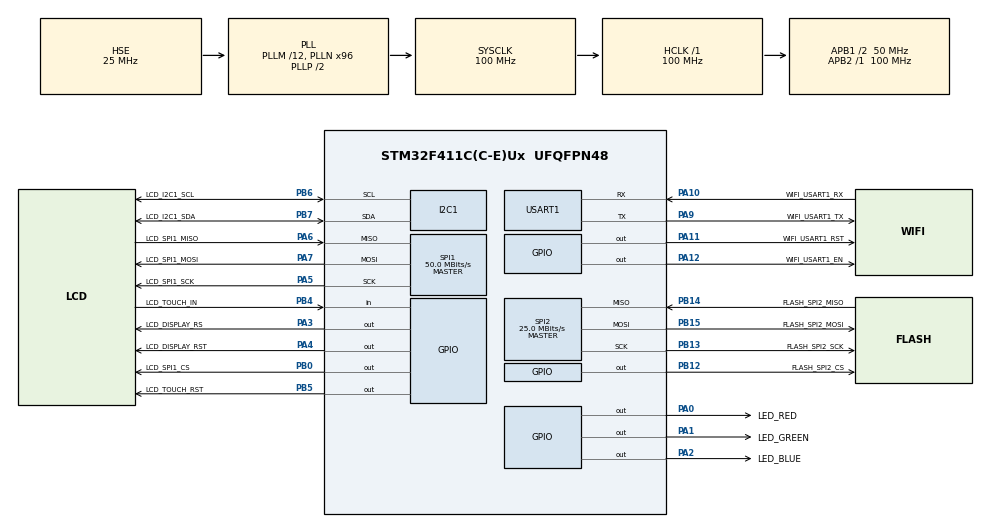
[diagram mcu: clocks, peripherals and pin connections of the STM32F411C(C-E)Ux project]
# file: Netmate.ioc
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FREERTOS.Tasks01=defaultTask,24,128,StartDefaultTask,Default,NULL,Dynamic,NULL,NULL
IWDG.Prescaler=IWDG_PRESCALER_64
Mcu.Family=STM32F4
Mcu.Name=STM32F411C(C-E)Ux
Mcu.Package=UFQFPN48
NVIC.PriorityGroup=NVIC_PRIORITYGROUP_4
NVIC.RTC_WKUP_IRQn=true\:5\:0\:false\:false\:true\:true\:true\:true\:true
NVIC.TIM3_IRQn=true\:15\:0\:false\:false\:true\:false\:false\:true\:true
NVIC.TimeBase=TIM3_IRQn
NVIC.TimeBaseIP=TIM3
PA0-WKUP.GPIO_Label=LED_RED
PA0-WKUP.GPIO_ModeDefaultOutputPP=GPIO_MODE_OUTPUT_PP
PA0-WKUP.GPIO_PuPd=GPIO_NOPULL
PA0-WKUP.PinState=GPIO_PIN_SET
PA0-WKUP.Signal=GPIO_Output
PA1.GPIO_Label=LED_GREEN
PA1.GPIO_PuPd=GPIO_NOPULL
PA1.PinState=GPIO_PIN_SET
PA1.Signal=GPIO_Output
PA10.GPIO_Label=WIFI_USART1_RX
PA10.Mode=Asynchronous
PA10.Signal=USART1_RX
PA11.GPIO_Label=WIFI_USART1_RST
PA11.Signal=GPIO_Output
PA12.GPIO_Label=WIFI_USART1_EN
PA12.Signal=GPIO_Output
PA13.Mode=Serial_Wire
PA13.Signal=SYS_JTMS-SWDIO
PA14.Mode=Serial_Wire
PA14.Signal=SYS_JTCK-SWCLK
PA2.GPIO_Label=LED_BLUE
PA2.GPIO_PuPd=GPIO_NOPULL
PA2.PinState=GPIO_PIN_SET
PA2.Signal=GPIO_Output
PA3.GPIO_Label=LCD_DISPLAY_RS
PA3.Signal=GPIO_Output
PA4.GPIO_Label=LCD_DISPLAY_RST
PA4.Signal=GPIO_Output
PA5.GPIO_Label=LCD_SPI1_SCK
PA5.Mode=Full_Duplex_Master
PA5.Signal=SPI1_SCK
PA6.GPIO_Label=LCD_SPI1_MISO
PA6.Mode=Full_Duplex_Master
PA6.Signal=SPI1_MISO
PA7.GPIO_Label=LCD_SPI1_MOSI
PA7.Mode=Full_Duplex_Master
PA7.Signal=SPI1_MOSI
PA9.GPIO_Label=WIFI_USART1_TX
PA9.Mode=Asynchronous
PA9.Signal=USART1_TX
PB0.GPIO_Label=LCD_SPI1_CS
PB0.Signal=GPIO_Output
PB12.GPIO_Label=FLASH_SPI2_CS
PB12.Signal=GPIO_Output
PB13.GPIO_Label=FLASH_SPI2_SCK
PB13.Mode=Full_Duplex_Master
PB13.Signal=SPI2_SCK
PB14.GPIO_Label=FLASH_SPI2_MISO
PB14.Mode=Full_Duplex_Master
PB14.Signal=SPI2_MISO
PB15.GPIO_Label=FLASH_SPI2_MOSI
PB15.Mode=Full_Duplex_Master
PB15.Signal=SPI2_MOSI
PB4.GPIO_Label=LCD_TOUCH_IN
PB4.Signal=GPIO_Input
PB5.GPIO_Label=LCD_TOUCH_RST
PB5.Signal=GPIO_Output
PB6.GPIO_Label=LCD_I2C1_SCL
PB6.Mode=I2C
PB6.Signal=I2C1_SCL
PB7.GPIO_Label=LCD_I2C1_SDA
PB7.Mode=I2C
PB7.Signal=I2C1_SDA
PC14-OSC32_IN.Mode=LSE-External-Oscillator
PC14-OSC32_IN.Signal=RCC_OSC32_IN
PC15-OSC32_OUT.Mode=LSE-External-Oscillator
PC15-OSC32_OUT.Signal=RCC_OSC32_OUT
PH0\ -\ OSC_IN.Mode=HSE-External-Oscillator
PH0\ -\ OSC_IN.Signal=RCC_OSC_IN
PH1\ -\ OSC_OUT.Mode=HSE-External-Oscillator
PH1\ -\ OSC_OUT.Signal=RCC_OSC_OUT
ProjectManager.HeapSize=0x200
ProjectManager.StackSize=0x400
ProjectManager.TargetToolchain=CMake
RCC.48MHZClocksFreq_Value=50000000
RCC.AHBFreq_Value=100000000
RCC.APB1CLKDivider=RCC_HCLK_DIV2
RCC.APB1Freq_Value=50000000
RCC.APB1TimFreq_Value=100000000
RCC.APB2Freq_Value=100000000
RCC.APB2TimFreq_Value=100000000
RCC.CortexFreq_Value=100000000
RCC.HCLKFreq_Value=100000000
RCC.HSE_VALUE=25000000
RCC.HSI_VALUE=16000000
RCC.PLLM=12
RCC.PLLN=96
RCC.PLLSourceVirtual=RCC_PLLSOURCE_HSE
RCC.RCC_RTC_Clock_Source=RCC_RTCCLKSOURCE_LSE
RCC.RCC_RTC_Clock_SourceVirtual=RCC_RTCCLKSOURCE_LSE
RCC.SYSCLKFreq_VALUE=100000000
RCC.SYSCLKSource=RCC_SYSCLKSOURCE_PLLCLK
RCC.VCOOutputFreq_Value=200000000
SPI1.CalculateBaudRate=50.0 MBits/s
SPI1.Direction=SPI_DIRECTION_2LINES
SPI1.Mode=SPI_MODE_MASTER
SPI1.VirtualType=VM_MASTER
SPI2.CalculateBaudRate=25.0 MBits/s
SPI2.Direction=SPI_DIRECTION_2LINES
SPI2.Mode=SPI_MODE_MASTER
SPI2.VirtualType=VM_MASTER
USART1.VirtualMode=VM_ASYNC
VP_FREERTOS_VS_CMSIS_V2.Mode=CMSIS_V2
VP_IWDG_VS_IWDG.Mode=IWDG_Activate
VP_RTC_VS_RTC_Activate.Mode=RTC_Enabled
VP_RTC_VS_RTC_WakeUp_intern.Mode=WakeUp
VP_SYS_VS_tim3.Mode=TIM3
board=custom

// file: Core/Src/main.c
/* USER CODE BEGIN Header */
/**
  ******************************************************************************
  * @file           : main.c
  * @brief          : Main program body
  ******************************************************************************
  * @attention
  *
  * Copyright (c) 2026 STMicroelectronics.
  * All rights reserved.
  *
  * This software is licensed under terms that can be found in the LICENSE file
  * in the root directory of this software component.
  * If no LICENSE file comes with this software, it is provided AS-IS.
  *
  ******************************************************************************
  */
/* USER CODE END Header */
#include "main.h"
#include "cmsis_os.h"
#include "i2c.h"
#include "iwdg.h"
#include "rtc.h"
#include "spi.h"
#include "usart.h"
#include "gpio.h"

/* USER CODE BEGIN PV */
volatile uint32_t boot_from_iwdg = 0;
/* USER CODE END PV */

void SystemClock_Config(void);
void MX_FREERTOS_Init(void);

int main(void)
{

  /* MCU Configuration--------------------------------------------------------*/

  /* Reset of all peripherals, Initializes the Flash interface and the Systick. */
  HAL_Init();

  /* Configure the system clock */
  SystemClock_Config();

  /* Initialize all configured peripherals */
  MX_GPIO_Init();
  MX_RTC_Init();
  MX_IWDG_Init();
  MX_USART1_UART_Init();
  MX_I2C1_Init();
  MX_SPI1_Init();
  MX_SPI2_Init();
  /* USER CODE BEGIN 2 */
  __HAL_DBGMCU_FREEZE_IWDG();
  boot_from_iwdg = (__HAL_RCC_GET_FLAG(RCC_FLAG_IWDGRST) != RESET) ? 1U : 0U;

  __HAL_RCC_CLEAR_RESET_FLAGS();
  /* USER CODE END 2 */

  /* Init scheduler */
  osKernelInitialize();  /* Call init function for freertos objects (in cmsis_os2.c) */
  MX_FREERTOS_Init();

  /* Start scheduler */
  osKernelStart();

  /* We should never get here as control is now taken by the scheduler */

  /* Infinite loop */
  while (1)
  {

  }
}

void SystemClock_Config(void)
{
  RCC_OscInitTypeDef RCC_OscInitStruct = {0};
  RCC_ClkInitTypeDef RCC_ClkInitStruct = {0};

  /** Configure the main internal regulator output voltage
  */
  __HAL_RCC_PWR_CLK_ENABLE();
  __HAL_PWR_VOLTAGESCALING_CONFIG(PWR_REGULATOR_VOLTAGE_SCALE1);

  /** Initializes the RCC Oscillators according to the specified parameters
  * in the RCC_OscInitTypeDef structure.
  */
  RCC_OscInitStruct.OscillatorType = RCC_OSCILLATORTYPE_LSI|RCC_OSCILLATORTYPE_HSE
                              |RCC_OSCILLATORTYPE_LSE;
  RCC_OscInitStruct.HSEState = RCC_HSE_ON;
  RCC_OscInitStruct.LSEState = RCC_LSE_ON;
  RCC_OscInitStruct.LSIState = RCC_LSI_ON;
  RCC_OscInitStruct.PLL.PLLState = RCC_PLL_ON;
  RCC_OscInitStruct.PLL.PLLSource = RCC_PLLSOURCE_HSE;
  RCC_OscInitStruct.PLL.PLLM = 12;
  RCC_OscInitStruct.PLL.PLLN = 96;
  RCC_OscInitStruct.PLL.PLLP = RCC_PLLP_DIV2;
  RCC_OscInitStruct.PLL.PLLQ = 4;
  if (HAL_RCC_OscConfig(&RCC_OscInitStruct) != HAL_OK)
  {
    Error_Handler();
  }

  /** Initializes the CPU, AHB and APB buses clocks
  */
  RCC_ClkInitStruct.ClockType = RCC_CLOCKTYPE_HCLK|RCC_CLOCKTYPE_SYSCLK
                              |RCC_CLOCKTYPE_PCLK1|RCC_CLOCKTYPE_PCLK2;
  RCC_ClkInitStruct.SYSCLKSource = RCC_SYSCLKSOURCE_PLLCLK;
  RCC_ClkInitStruct.AHBCLKDivider = RCC_SYSCLK_DIV1;
  RCC_ClkInitStruct.APB1CLKDivider = RCC_HCLK_DIV2;
  RCC_ClkInitStruct.APB2CLKDivider = RCC_HCLK_DIV1;

  if (HAL_RCC_ClockConfig(&RCC_ClkInitStruct, FLASH_LATENCY_3) != HAL_OK)
  {
    Error_Handler();
  }
}

void HAL_TIM_PeriodElapsedCallback(TIM_HandleTypeDef *htim)
{
  if (htim->Instance == TIM3)
  {
    HAL_IncTick();
  }
}

void Error_Handler(void)
{
  __disable_irq();
  while (1)
  {
  }
}

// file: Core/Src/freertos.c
/* USER CODE BEGIN Header */
/**
  ******************************************************************************
  * File Name          : freertos.c
  * Description        : Code for freertos applications
  ******************************************************************************
  * @attention
  *
  * Copyright (c) 2026 STMicroelectronics.
  * All rights reserved.
  *
  * This software is licensed under terms that can be found in the LICENSE file
  * in the root directory of this software component.
  * If no LICENSE file comes with this software, it is provided AS-IS.
  *
  ******************************************************************************
  */
/* USER CODE END Header */

#include "FreeRTOS.h"
#include "task.h"
#include "main.h"
#include "cmsis_os.h"
#include "iwdg.h"

/* Definitions for defaultTask */
osThreadId_t defaultTaskHandle;
const osThreadAttr_t defaultTask_attributes = {
  .name = "defaultTask",
  .stack_size = 128 * 4,
  .priority = (osPriority_t) osPriorityNormal,
};

void StartDefaultTask(void *argument);

void MX_FREERTOS_Init(void); /* (MISRA C 2004 rule 8.1) */

void MX_FREERTOS_Init(void) {

  /* Create the thread(s) */
  /* creation of defaultTask */
  defaultTaskHandle = osThreadNew(StartDefaultTask, NULL, &defaultTask_attributes);

}

void StartDefaultTask(void *argument)
{
  /* USER CODE BEGIN StartDefaultTask */
  /* Infinite loop */
  for(;;)
  {
      HAL_GPIO_TogglePin(LED_RED_GPIO_Port, LED_RED_Pin);
      //HAL_IWDG_Refresh(&hiwdg);
      osDelay(500);
  }
  /* USER CODE END StartDefaultTask */
}
